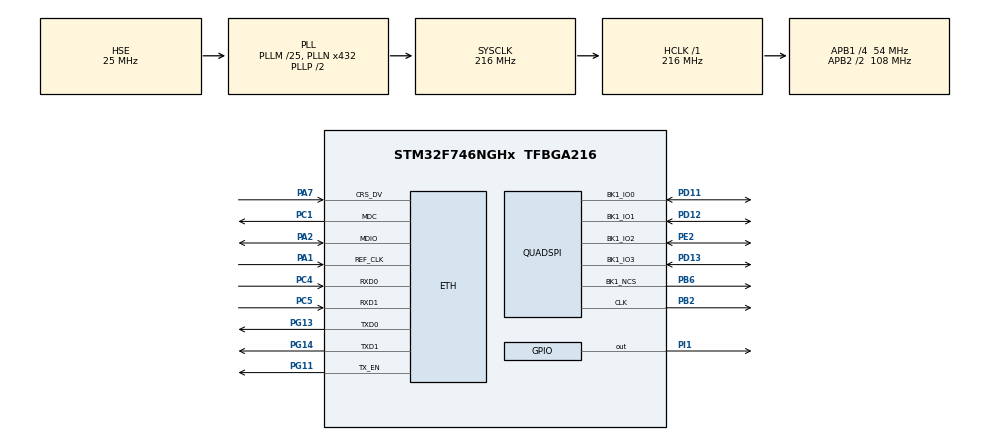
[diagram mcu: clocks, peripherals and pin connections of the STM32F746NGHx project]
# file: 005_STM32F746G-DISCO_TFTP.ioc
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Mcu.Family=STM32F7
RCC.CortexFreq_Value=216000000
QUADSPI.ClockPrescaler=1
CORTEX_M7.PREFETCH_ENABLE=1
PC5.Mode=RMII
PG13.Signal=ETH_TXD0
PG11.Signal=ETH_TX_EN
RCC.SYSCLKSource=RCC_SYSCLKSOURCE_PLLCLK
ProjectManager.StackSize=0x400
LWIP.NETMASK_ADDRESS=255.255.255.000
PD13.Signal=QUADSPI_BK1_IO3
PH0/OSC_IN.Mode=HSE-External-Oscillator
RCC.HCLKFreq_Value=216000000
PE2.Mode=Single Bank 1
RCC.APB2TimFreq_Value=216000000
PB6.Signal=QUADSPI_BK1_NCS
PB6.Mode=Single Bank 1
PH1/OSC_OUT.Signal=RCC_OSC_OUT
QUADSPI.FlashSize=23
RCC.AHBFreq_Value=216000000
NVIC.ETH_IRQn=true\:0\:0\:false\:false\:true\:true\:true
RCC.HSE_VALUE=25000000
PB2.Signal=QUADSPI_CLK
PG14.Mode=RMII
LWIP.MEM_SIZE=10*1024
NVIC.TIM2_IRQn=true\:0\:0\:false\:false\:true\:true\:true
PE2.Signal=QUADSPI_BK1_IO2
PG13.Mode=RMII
PH1/OSC_OUT.Mode=HSE-External-Oscillator
QUADSPI.SampleShifting=QSPI_SAMPLE_SHIFTING_HALFCYCLE
Mcu.Package=TFBGA216
TIM2.Prescaler=1000
PD12.Signal=QUADSPI_BK1_IO1
RCC.APB2CLKDivider=RCC_HCLK_DIV2
RCC.APB1TimFreq_Value=108000000
PC5.Signal=ETH_RXD1
PC4.Mode=RMII
LWIP.IP_ADDRESS=192.168.000.123
RCC.PLLSourceVirtual=RCC_PLLSOURCE_HSE
QUADSPI.ChipSelectHighTime=QSPI_CS_HIGH_TIME_6_CYCLE
CORTEX_M7.CPU_ICache=Enabled
PA7.Mode=RMII
PC4.Signal=ETH_RXD0
LWIP.LWIP_DHCP=0
RCC.APB1CLKDivider=RCC_HCLK_DIV4
ETH.PhyAddress=0
VP_LWIP_VS_Enabled.Mode=Enabled
LWIP.GATEWAY_ADDRESS=192.168.000.001
ProjectManager.TargetToolchain=STM32CubeIDE
PD13.Mode=Single Bank 1
RCC.USBFreq_Value=216000000
RCC.LSE_VALUE=32768
PA1.Signal=ETH_REF_CLK
PG14.Signal=ETH_TXD1
board=STM32F746G-DISCO
RCC.VCOOutputFreq_Value=432000000
PH0/OSC_IN.Signal=RCC_OSC_IN
LWIP.LWIP_TFTP=0
RCC.APB2Freq_Value=108000000
PA1.Mode=RMII
VP_TIM2_VS_ClockSourceINT.Mode=Internal
PI1.Signal=GPIO_Output
QUADSPI.FifoThreshold=4
TIM2.Period=21600
Mcu.Name=STM32F746NGHx
PA2.Signal=ETH_MDIO
RCC.SYSCLKFreq_VALUE=216000000
ETH.MediaInterface=ETH_MEDIA_INTERFACE_RMII
PD12.Mode=Single Bank 1
PD11.Signal=QUADSPI_BK1_IO0
PB2.Mode=Single Bank 1
PG11.Mode=RMII
ProjectManager.HeapSize=0x200
LWIP.Version=v2.1.2_Cube
PD11.Mode=Single Bank 1
RCC.HSI_VALUE=16000000
NVIC.PriorityGroup=NVIC_PRIORITYGROUP_4
RCC.PLLM=25
RCC.PLLN=432
PA2.Mode=RMII
TIM2.AutoReloadPreload=TIM_AUTORELOAD_PRELOAD_ENABLE
CORTEX_M7.CPU_DCache=Enabled
RCC.APB1Freq_Value=54000000
PC1.Signal=ETH_MDC
PC1.Mode=RMII
PA7.Signal=ETH_CRS_DV

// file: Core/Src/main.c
/* USER CODE BEGIN Header */
/**
  ******************************************************************************
  * @file           : main.c
  * @brief          : Main program body
  ******************************************************************************
  * @attention
  *
  * <h2><center>&copy; Copyright (c) 2023 STMicroelectronics.
  * All rights reserved.</center></h2>
  *
  * This software component is licensed by ST under BSD 3-Clause license,
  * the "License"; You may not use this file except in compliance with the
  * License. You may obtain a copy of the License at:
  *                        opensource.org/licenses/BSD-3-Clause
  *
  ******************************************************************************
  */
/* USER CODE END Header */
#include "main.h"
#include "lwip.h"
#include "quadspi.h"
#include "tim.h"
#include "gpio.h"

/* USER CODE BEGIN Includes */
// #include  "udpServerRAW.h"
// #include  "tcpServerRAW.h"
#include "tftpserver.h"
#include "flash.h"
#include <string.h>
/* USER CODE END Includes */

/* USER CODE BEGIN PV */
struct netif gnetif;
/* USER CODE END PV */

void SystemClock_Config(void);

/* USER CODE BEGIN 0 */
//uint8_t *writeBuf = "Tdieney";
//uint8_t readBuf[100];
/* USER CODE END 0 */

int main(void)
{

  /* Enable I-Cache---------------------------------------------------------*/
  SCB_EnableICache();

  /* Enable D-Cache---------------------------------------------------------*/
  SCB_EnableDCache();

  /* MCU Configuration--------------------------------------------------------*/

  /* Reset of all peripherals, Initializes the Flash interface and the Systick. */
  HAL_Init();

  /* Configure the system clock */
  SystemClock_Config();

  /* Initialize all configured peripherals */
  MX_GPIO_Init();
  MX_LWIP_Init();
  MX_TIM2_Init();
  MX_QUADSPI_Init();
  /* USER CODE BEGIN 2 */
  HAL_TIM_Base_Start_IT(&htim2);

  /* Initialize the QSPI */
  if (CSP_QUADSPI_Init() != HAL_OK)
  {
    Error_Handler();
  }

  // CSP_QSPI_Erase_Chip() may take MCU to the Error_Handler()
  // if (CSP_QSPI_Erase_Chip() != HAL_OK)
  // {
  //   Error_Handler();
  // }

  // if (CSP_QSPI_Write(writeBuf, 0, strlen(writeBuf)) != HAL_OK)
  // {
  //   Error_Handler();
  // }

  // if (CSP_QSPI_Read(readBuf, 0, 100) != HAL_OK)
  // {
  //   Error_Handler();
  // }

  // Initialize the UDP server
  // udpServer_init();
  // Initialize the TCP server
  // tcp_server_init();
  // Initialize the TFTP server
  tftpd_init();

  /* USER CODE END 2 */

  /* Infinite loop */
  while (1)
  {

    /* USER CODE BEGIN 3 */
  	ethernetif_input(&gnetif);
  	sys_check_timeouts();
  }
  /* USER CODE END 3 */
}

void SystemClock_Config(void)
{
  RCC_OscInitTypeDef RCC_OscInitStruct = {0};
  RCC_ClkInitTypeDef RCC_ClkInitStruct = {0};

  /** Configure the main internal regulator output voltage
  */
  __HAL_RCC_PWR_CLK_ENABLE();
  __HAL_PWR_VOLTAGESCALING_CONFIG(PWR_REGULATOR_VOLTAGE_SCALE1);
  /** Initializes the RCC Oscillators according to the specified parameters
  * in the RCC_OscInitTypeDef structure.
  */
  RCC_OscInitStruct.OscillatorType = RCC_OSCILLATORTYPE_HSE;
  RCC_OscInitStruct.HSEState = RCC_HSE_ON;
  RCC_OscInitStruct.PLL.PLLState = RCC_PLL_ON;
  RCC_OscInitStruct.PLL.PLLSource = RCC_PLLSOURCE_HSE;
  RCC_OscInitStruct.PLL.PLLM = 25;
  RCC_OscInitStruct.PLL.PLLN = 432;
  RCC_OscInitStruct.PLL.PLLP = RCC_PLLP_DIV2;
  RCC_OscInitStruct.PLL.PLLQ = 2;
  if (HAL_RCC_OscConfig(&RCC_OscInitStruct) != HAL_OK)
  {
    Error_Handler();
  }
  /** Activate the Over-Drive mode
  */
  if (HAL_PWREx_EnableOverDrive() != HAL_OK)
  {
    Error_Handler();
  }
  /** Initializes the CPU, AHB and APB buses clocks
  */
  RCC_ClkInitStruct.ClockType = RCC_CLOCKTYPE_HCLK|RCC_CLOCKTYPE_SYSCLK
                              |RCC_CLOCKTYPE_PCLK1|RCC_CLOCKTYPE_PCLK2;
  RCC_ClkInitStruct.SYSCLKSource = RCC_SYSCLKSOURCE_PLLCLK;
  RCC_ClkInitStruct.AHBCLKDivider = RCC_SYSCLK_DIV1;
  RCC_ClkInitStruct.APB1CLKDivider = RCC_HCLK_DIV4;
  RCC_ClkInitStruct.APB2CLKDivider = RCC_HCLK_DIV2;

  if (HAL_RCC_ClockConfig(&RCC_ClkInitStruct, FLASH_LATENCY_7) != HAL_OK)
  {
    Error_Handler();
  }
}

/* USER CODE BEGIN 4 */
void HAL_TIM_PeriodElapsedCallback(TIM_HandleTypeDef *htim)
{
	GPIOI->ODR ^= 1UL << 1;
}
/* USER CODE END 4 */

void Error_Handler(void)
{
  __disable_irq();
  while (1)
  {
  }
}

/************************ (C) COPYRIGHT STMicroelectronics *****END OF FILE****/
